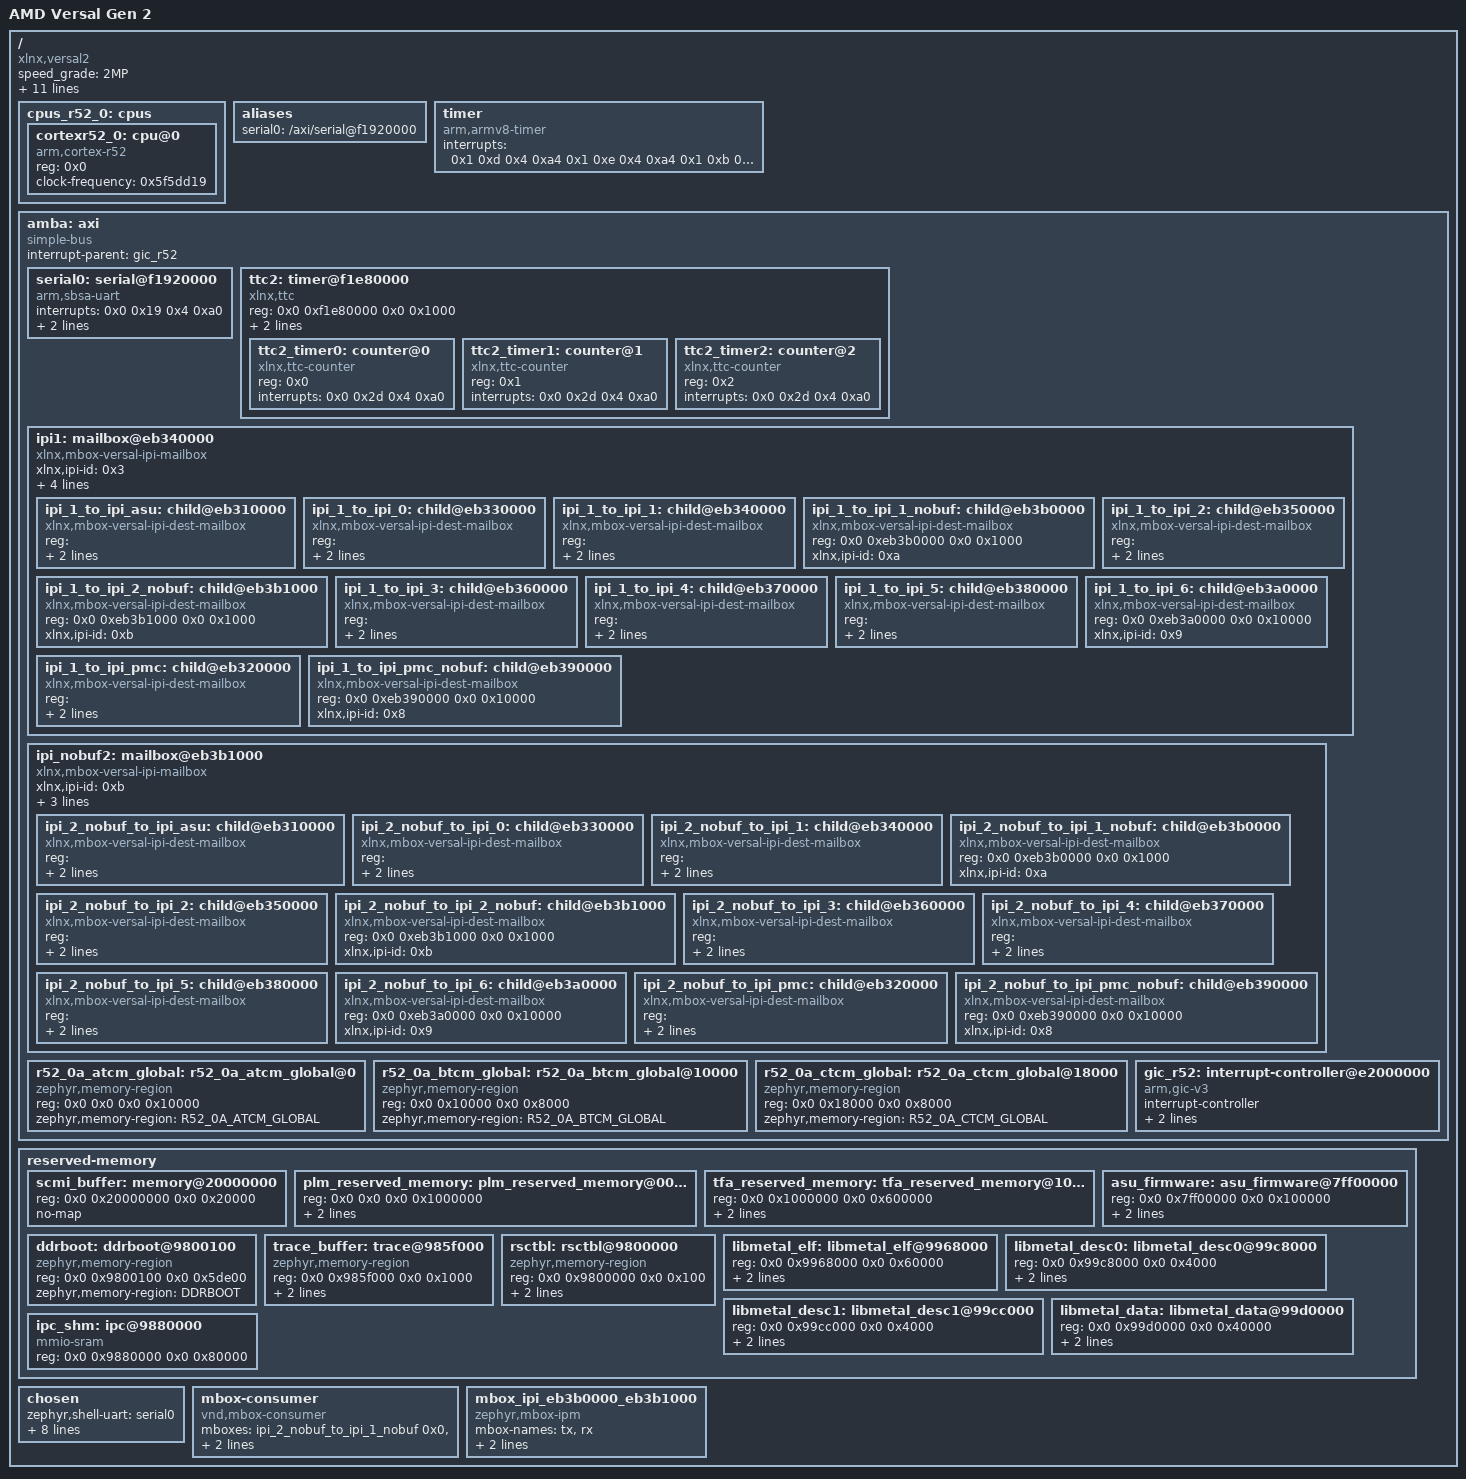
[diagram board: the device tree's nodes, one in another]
/dts-v1/;
/ {
        speed_grade = "2MP";
        family = "Versal_2VE_2VM";
        slrcount = <0x1>;
        variant = "Versal_2VE_2VM_Small";
        xlnx,ddrmc5-i2c-master = "PMC";
        xlnx,ddrmc5-debug-elf = "false";
        device_id = "xc2vm3654";
        vivado-version = "2026.2";
        board = "vmk365";
        interrupt-parent = <&gic_r52>;
        #size-cells = <0x2>;
        #address-cells = <0x2>;
        model = "AMD Versal Gen 2";
        compatible = "xlnx,versal2";
        pruned-sdt = <0x1>;

        cpus_r52_0: cpus {
                phandle = <0xfb>;
                #size-cells = <0x0>;
                #address-cells = <0x1>;

                cortexr52_0: cpu@0 {
                        phandle = <0xb8>;
                        reg = <0x0>;
                        device_type = "cpu";
                        compatible = "arm,cortex-r52";
                        clock-frequency = <0x5f5dd19>;
                };
        };

        aliases {
                serial0 = "/axi/serial@f1920000";
        };

        timer: timer {
                phandle = <0x116>;
                interrupts = <0x1 0xd 0x4 0xa4 0x1 0xe 0x4 0xa4 0x1 0xb 0x4 0xa4 0x1 0xa 0x4 0xa4>;
                compatible = "arm,armv8-timer";
        };

        amba: axi {
                phandle = <0x2>;
                interrupt-parent = <&gic_r52>;
                ranges;
                #size-cells = <0x2>;
                #address-cells = <0x2>;
                bootph-all;
                compatible = "simple-bus";

                serial0: serial@f1920000 {
                        phandle = <0x93>;
                        interrupts = <0x0 0x19 0x4 0xa0>;
                        interrupt-parent = <&gic_r52>;
                        reg = <0x0 0xf1920000 0x0 0x1000>;
                        status = "okay";
                        compatible = "arm,sbsa-uart";
                        interrupt-names = "serial0";
                };

                ttc2: timer@f1e80000 {
                        phandle = <0x9e>;
                        reg = <0x0 0xf1e80000 0x0 0x1000>;
                        timer-width = <0x20>;
                        status = "okay";
                        compatible = "xlnx,ttc";
                        clock-frequency = <0x8f0cba9>;
                        #address-cells = <0x1>;
                        #size-cells = <0x0>;

                        ttc2_timer0: counter@0 {
                                phandle = <0x1>;
                                compatible = "xlnx,ttc-counter";
                                reg = <0x0>;
                                interrupts = <0x0 0x2d 0x4 0xa0>;
                        };

                        ttc2_timer1: counter@1 {
                                phandle = <0x3>;
                                compatible = "xlnx,ttc-counter";
                                reg = <0x1>;
                                interrupts = <0x0 0x2d 0x4 0xa0>;
                        };

                        ttc2_timer2: counter@2 {
                                phandle = <0x4>;
                                compatible = "xlnx,ttc-counter";
                                reg = <0x2>;
                                interrupts = <0x0 0x2d 0x4 0xa0>;
                        };
                };

                ipi1: mailbox@eb340000 {
                        phandle = <0xb4>;
                        reg-names = "ctrl", "msg";
                        #size-cells = <0x2>;
                        #address-cells = <0x2>;
                        xlnx,ipi-id = <0x3>;
                        reg = <0x0 0xeb340000 0x0 0x10000 0x0 0xeb3f0600 0x0 0x200>;
                        interrupts = <0x0 0x3a 0x4 0xa0>;
                        interrupt-parent = <&gic_r52>;
                        compatible = "xlnx,mbox-versal-ipi-mailbox";

                        ipi_1_to_ipi_asu: child@eb310000 {
                                phandle = <0x15e>;
                                reg-names = "ctrl", "msg";
                                reg = <0x0 0xeb310000 0x0 0x10000 0x0 0xeb3f0000 0x0 0x200>;
                                xlnx,ipi-id = <0x0>;
                                #mbox-cells = <0x1>;
                                compatible = "xlnx,mbox-versal-ipi-dest-mailbox";
                        };

                        ipi_1_to_ipi_0: child@eb330000 {
                                phandle = <0x15f>;
                                reg-names = "ctrl", "msg";
                                reg = <0x0 0xeb330000 0x0 0x10000 0x0 0xeb3f0400 0x0 0x200>;
                                xlnx,ipi-id = <0x2>;
                                #mbox-cells = <0x1>;
                                compatible = "xlnx,mbox-versal-ipi-dest-mailbox";
                        };

                        ipi_1_to_ipi_1: child@eb340000 {
                                phandle = <0x160>;
                                reg-names = "ctrl", "msg";
                                reg = <0x0 0xeb340000 0x0 0x10000 0x0 0xeb3f0600 0x0 0x200>;
                                xlnx,ipi-id = <0x3>;
                                #mbox-cells = <0x1>;
                                compatible = "xlnx,mbox-versal-ipi-dest-mailbox";
                        };

                        ipi_1_to_ipi_1_nobuf: child@eb3b0000 {
                                phandle = <0x161>;
                                reg-names = "ctrl";
                                reg = <0x0 0xeb3b0000 0x0 0x1000>;
                                xlnx,ipi-id = <0xa>;
                                #mbox-cells = <0x1>;
                                compatible = "xlnx,mbox-versal-ipi-dest-mailbox";
                        };

                        ipi_1_to_ipi_2: child@eb350000 {
                                phandle = <0x162>;
                                reg-names = "ctrl", "msg";
                                reg = <0x0 0xeb350000 0x0 0x10000 0x0 0xeb3f0800 0x0 0x200>;
                                xlnx,ipi-id = <0x4>;
                                #mbox-cells = <0x1>;
                                compatible = "xlnx,mbox-versal-ipi-dest-mailbox";
                        };

                        ipi_1_to_ipi_2_nobuf: child@eb3b1000 {
                                phandle = <0x163>;
                                reg-names = "ctrl";
                                reg = <0x0 0xeb3b1000 0x0 0x1000>;
                                xlnx,ipi-id = <0xb>;
                                #mbox-cells = <0x1>;
                                compatible = "xlnx,mbox-versal-ipi-dest-mailbox";
                        };

                        ipi_1_to_ipi_3: child@eb360000 {
                                phandle = <0x164>;
                                reg-names = "ctrl", "msg";
                                reg = <0x0 0xeb360000 0x0 0x10000 0x0 0xeb3f0a00 0x0 0x200>;
                                xlnx,ipi-id = <0x5>;
                                #mbox-cells = <0x1>;
                                compatible = "xlnx,mbox-versal-ipi-dest-mailbox";
                        };

                        ipi_1_to_ipi_4: child@eb370000 {
                                phandle = <0x165>;
                                reg-names = "ctrl", "msg";
                                reg = <0x0 0xeb370000 0x0 0x10000 0x0 0xeb3f0c00 0x0 0x200>;
                                xlnx,ipi-id = <0x6>;
                                #mbox-cells = <0x1>;
                                compatible = "xlnx,mbox-versal-ipi-dest-mailbox";
                        };

                        ipi_1_to_ipi_5: child@eb380000 {
                                phandle = <0x166>;
                                reg-names = "ctrl", "msg";
                                reg = <0x0 0xeb380000 0x0 0x10000 0x0 0xeb3f0e00 0x0 0x200>;
                                xlnx,ipi-id = <0x7>;
                                #mbox-cells = <0x1>;
                                compatible = "xlnx,mbox-versal-ipi-dest-mailbox";
                        };

                        ipi_1_to_ipi_6: child@eb3a0000 {
                                phandle = <0x167>;
                                reg-names = "ctrl";
                                reg = <0x0 0xeb3a0000 0x0 0x10000>;
                                xlnx,ipi-id = <0x9>;
                                #mbox-cells = <0x1>;
                                compatible = "xlnx,mbox-versal-ipi-dest-mailbox";
                        };

                        ipi_1_to_ipi_pmc: child@eb320000 {
                                phandle = <0x168>;
                                reg-names = "ctrl", "msg";
                                reg = <0x0 0xeb320000 0x0 0x10000 0x0 0xeb3f0200 0x0 0x200>;
                                xlnx,ipi-id = <0x1>;
                                #mbox-cells = <0x1>;
                                compatible = "xlnx,mbox-versal-ipi-dest-mailbox";
                        };

                        ipi_1_to_ipi_pmc_nobuf: child@eb390000 {
                                phandle = <0x169>;
                                reg-names = "ctrl";
                                reg = <0x0 0xeb390000 0x0 0x10000>;
                                xlnx,ipi-id = <0x8>;
                                #mbox-cells = <0x1>;
                                compatible = "xlnx,mbox-versal-ipi-dest-mailbox";
                        };
                };

                ipi_nobuf2: mailbox@eb3b1000 {
                        phandle = <0xb5>;
                        reg-names = "ctrl";
                        #size-cells = <0x2>;
                        #address-cells = <0x2>;
                        xlnx,ipi-id = <0xb>;
                        reg = <0x0 0xeb3b1000 0x0 0x1000>;
                        interrupts = <0x0 0x41 0x4 0xa0>;
                        interrupt-parent = <&gic_r52>;
                        compatible = "xlnx,mbox-versal-ipi-mailbox";

                        ipi_2_nobuf_to_ipi_asu: child@eb310000 {
                                phandle = <0x1b2>;
                                reg-names = "ctrl", "msg";
                                reg = <0x0 0xeb310000 0x0 0x10000 0x0 0xeb3f0000 0x0 0x200>;
                                xlnx,ipi-id = <0x0>;
                                #mbox-cells = <0x1>;
                                compatible = "xlnx,mbox-versal-ipi-dest-mailbox";
                        };

                        ipi_2_nobuf_to_ipi_0: child@eb330000 {
                                phandle = <0x1b3>;
                                reg-names = "ctrl", "msg";
                                reg = <0x0 0xeb330000 0x0 0x10000 0x0 0xeb3f0400 0x0 0x200>;
                                xlnx,ipi-id = <0x2>;
                                #mbox-cells = <0x1>;
                                compatible = "xlnx,mbox-versal-ipi-dest-mailbox";
                        };

                        ipi_2_nobuf_to_ipi_1: child@eb340000 {
                                phandle = <0x1b4>;
                                reg-names = "ctrl", "msg";
                                reg = <0x0 0xeb340000 0x0 0x10000 0x0 0xeb3f0600 0x0 0x200>;
                                xlnx,ipi-id = <0x3>;
                                #mbox-cells = <0x1>;
                                compatible = "xlnx,mbox-versal-ipi-dest-mailbox";
                        };

                        ipi_2_nobuf_to_ipi_1_nobuf: child@eb3b0000 {
                                phandle = <0x1b5>;
                                reg-names = "ctrl";
                                reg = <0x0 0xeb3b0000 0x0 0x1000>;
                                xlnx,ipi-id = <0xa>;
                                #mbox-cells = <0x1>;
                                compatible = "xlnx,mbox-versal-ipi-dest-mailbox";
                        };

                        ipi_2_nobuf_to_ipi_2: child@eb350000 {
                                phandle = <0x1b6>;
                                reg-names = "ctrl", "msg";
                                reg = <0x0 0xeb350000 0x0 0x10000 0x0 0xeb3f0800 0x0 0x200>;
                                xlnx,ipi-id = <0x4>;
                                #mbox-cells = <0x1>;
                                compatible = "xlnx,mbox-versal-ipi-dest-mailbox";
                        };

                        ipi_2_nobuf_to_ipi_2_nobuf: child@eb3b1000 {
                                phandle = <0x1b7>;
                                reg-names = "ctrl";
                                reg = <0x0 0xeb3b1000 0x0 0x1000>;
                                xlnx,ipi-id = <0xb>;
                                #mbox-cells = <0x1>;
                                compatible = "xlnx,mbox-versal-ipi-dest-mailbox";
                        };

                        ipi_2_nobuf_to_ipi_3: child@eb360000 {
                                phandle = <0x1b8>;
                                reg-names = "ctrl", "msg";
                                reg = <0x0 0xeb360000 0x0 0x10000 0x0 0xeb3f0a00 0x0 0x200>;
                                xlnx,ipi-id = <0x5>;
                                #mbox-cells = <0x1>;
                                compatible = "xlnx,mbox-versal-ipi-dest-mailbox";
                        };

                        ipi_2_nobuf_to_ipi_4: child@eb370000 {
                                phandle = <0x1b9>;
                                reg-names = "ctrl", "msg";
                                reg = <0x0 0xeb370000 0x0 0x10000 0x0 0xeb3f0c00 0x0 0x200>;
                                xlnx,ipi-id = <0x6>;
                                #mbox-cells = <0x1>;
                                compatible = "xlnx,mbox-versal-ipi-dest-mailbox";
                        };

                        ipi_2_nobuf_to_ipi_5: child@eb380000 {
                                phandle = <0x1ba>;
                                reg-names = "ctrl", "msg";
                                reg = <0x0 0xeb380000 0x0 0x10000 0x0 0xeb3f0e00 0x0 0x200>;
                                xlnx,ipi-id = <0x7>;
                                #mbox-cells = <0x1>;
                                compatible = "xlnx,mbox-versal-ipi-dest-mailbox";
                        };

                        ipi_2_nobuf_to_ipi_6: child@eb3a0000 {
                                phandle = <0x1bb>;
                                reg-names = "ctrl";
                                reg = <0x0 0xeb3a0000 0x0 0x10000>;
                                xlnx,ipi-id = <0x9>;
                                #mbox-cells = <0x1>;
                                compatible = "xlnx,mbox-versal-ipi-dest-mailbox";
                        };

                        ipi_2_nobuf_to_ipi_pmc: child@eb320000 {
                                phandle = <0x1bc>;
                                reg-names = "ctrl", "msg";
                                reg = <0x0 0xeb320000 0x0 0x10000 0x0 0xeb3f0200 0x0 0x200>;
                                xlnx,ipi-id = <0x1>;
                                #mbox-cells = <0x1>;
                                compatible = "xlnx,mbox-versal-ipi-dest-mailbox";
                        };

                        ipi_2_nobuf_to_ipi_pmc_nobuf: child@eb390000 {
                                phandle = <0x1bd>;
                                reg-names = "ctrl";
                                reg = <0x0 0xeb390000 0x0 0x10000>;
                                xlnx,ipi-id = <0x8>;
                                #mbox-cells = <0x1>;
                                compatible = "xlnx,mbox-versal-ipi-dest-mailbox";
                        };
                };

                r52_0a_atcm_global: r52_0a_atcm_global@0 {
                        phandle = <0x21>;
                        reg = <0x0 0x0 0x0 0x10000>;
                        compatible = "zephyr,memory-region", "xlnx,tcm";
                        status = "okay";
                        zephyr,memory-region = "R52_0A_ATCM_GLOBAL";
                };

                r52_0a_btcm_global: r52_0a_btcm_global@10000 {
                        phandle = <0x22>;
                        reg = <0x0 0x10000 0x0 0x8000>;
                        compatible = "zephyr,memory-region", "xlnx,tcm";
                        status = "okay";
                        zephyr,memory-region = "R52_0A_BTCM_GLOBAL";
                };

                r52_0a_ctcm_global: r52_0a_ctcm_global@18000 {
                        phandle = <0x23>;
                        reg = <0x0 0x18000 0x0 0x8000>;
                        compatible = "zephyr,memory-region", "xlnx,tcm";
                        status = "okay";
                        zephyr,memory-region = "R52_0A_CTCM_GLOBAL";
                };

                gic_r52: interrupt-controller@e2000000 {
                        phandle = <0xb6>;
                        compatible = "arm,gic-v3", "arm,gic";
                        #interrupt-cells = <0x4>;
                        interrupt-controller;
                        reg = <0x0 0xe2000000 0x0 0x10000 0x0 0xe2100000 0x0 0x80000>;
                        status = "okay";
                };
        };

        reserved-memory {
                #address-cells = <0x2>;
                #size-cells = <0x2>;
                ranges;

                scmi_buffer: memory@20000000 {
                        phandle = <0x1ed>;
                        reg = <0x0 0x20000000 0x0 0x20000>;
                        no-map;
                };

                plm_reserved_memory: plm_reserved_memory@00000000 {
                        phandle = <0x1fd>;
                        reg = <0x0 0x0 0x0 0x1000000>;
                        no-map;
                        label = "plm_reserved_memory";
                };

                tfa_reserved_memory: tfa_reserved_memory@1000000 {
                        phandle = <0x1fe>;
                        reg = <0x0 0x1000000 0x0 0x600000>;
                        no-map;
                        label = "tfa_reserved_memory";
                };

                asu_firmware: asu_firmware@7ff00000 {
                        phandle = <0x201>;
                        reg = <0x0 0x7ff00000 0x0 0x100000>;
                        no-map;
                        label = "asu_firmware";
                };

                ddrboot: ddrboot@9800100 {
                        phandle = <0x205>;
                        reg = <0x0 0x9800100 0x0 0x5de00>;
                        compatible = "zephyr,memory-region";
                        zephyr,memory-region = "DDRBOOT";
                };

                trace_buffer: trace@985f000 {
                        phandle = <0x206>;
                        reg = <0x0 0x985f000 0x0 0x1000>;
                        compatible = "zephyr,memory-region";
                        zephyr,memory-region = "TRACE_BUFFER";
                        zephyr,memory-attr = <0x200000>;
                };

                rsctbl: rsctbl@9800000 {
                        phandle = <0x207>;
                        reg = <0x0 0x9800000 0x0 0x100>;
                        compatible = "zephyr,memory-region";
                        zephyr,memory-region = "RSCTBL";
                        zephyr,memory-attr = <0x200000>;
                };

                libmetal_elf: libmetal_elf@9968000 {
                        phandle = <0x20e>;
                        reg = <0x0 0x9968000 0x0 0x60000>;
                        no-map;
                        label = "libmetal_elf";
                };

                libmetal_desc0: libmetal_desc0@99c8000 {
                        phandle = <0x20b>;
                        reg = <0x0 0x99c8000 0x0 0x4000>;
                        no-map;
                        label = "libmetal_desc0";
                };

                libmetal_desc1: libmetal_desc1@99cc000 {
                        phandle = <0x20c>;
                        reg = <0x0 0x99cc000 0x0 0x4000>;
                        no-map;
                        label = "libmetal_desc1";
                };

                libmetal_data: libmetal_data@99d0000 {
                        phandle = <0x20d>;
                        reg = <0x0 0x99d0000 0x0 0x40000>;
                        no-map;
                        label = "libmetal_data";
                };

                ipc_shm: ipc@9880000 {
                        phandle = <0x20f>;
                        reg = <0x0 0x9880000 0x0 0x80000>;
                        compatible = "mmio-sram";
                        status = "okay";
                };
        };

        chosen {
                zephyr,shell-uart = "serial0";
                zephyr,console = "serial0";
                bootargs = "console=ttyAMA0,115200";
                stdout-path = "serial0:115200n8";
                zephyr,ram-console = "/reserved-memory/trace@985f000";
                zephyr,ipc_shm = "/reserved-memory/ipc@9880000";
                zephyr,sram = "/axi/r52_0a_atcm_global@0";
                zephyr,ipc = "/mbox_ipi_eb3b0000_eb3b1000";
        };

        mbox-consumer {
                compatible = "vnd,mbox-consumer";
                mboxes = <&ipi_2_nobuf_to_ipi_1_nobuf 0x0>,
                 <&ipi_2_nobuf_to_ipi_1_nobuf 0x1>;
                mbox-names = "tx", "rx";
        };

        mbox_ipi_eb3b0000_eb3b1000 {
                compatible = "zephyr,mbox-ipm";
                mbox-names = "tx", "rx";
                status = "okay";
                mboxes = <&ipi_2_nobuf_to_ipi_1_nobuf 0x0>,
                 <&ipi_2_nobuf_to_ipi_1_nobuf 0x1>;
        };

        __symbols__ {
                cpus_r52_0 = "/cpus";
                cortexr52_0 = "/cpus/cpu@0";
                timer = "/timer";
                amba = "/axi";
                serial0 = "/axi/serial@f1920000";
                ttc2 = "/axi/timer@f1e80000";
                ttc2_timer0 = "/axi/timer@f1e80000/counter@0";
                ttc2_timer1 = "/axi/timer@f1e80000/counter@1";
                ttc2_timer2 = "/axi/timer@f1e80000/counter@2";
                ipi1 = "/axi/mailbox@eb340000";
                ipi_1_to_ipi_asu = "/axi/mailbox@eb340000/child@eb310000";
                ipi_1_to_ipi_0 = "/axi/mailbox@eb340000/child@eb330000";
                ipi_1_to_ipi_1 = "/axi/mailbox@eb340000/child@eb340000";
                ipi_1_to_ipi_1_nobuf = "/axi/mailbox@eb340000/child@eb3b0000";
                ipi_1_to_ipi_2 = "/axi/mailbox@eb340000/child@eb350000";
                ipi_1_to_ipi_2_nobuf = "/axi/mailbox@eb340000/child@eb3b1000";
                ipi_1_to_ipi_3 = "/axi/mailbox@eb340000/child@eb360000";
                ipi_1_to_ipi_4 = "/axi/mailbox@eb340000/child@eb370000";
                ipi_1_to_ipi_5 = "/axi/mailbox@eb340000/child@eb380000";
                ipi_1_to_ipi_6 = "/axi/mailbox@eb340000/child@eb3a0000";
                ipi_1_to_ipi_pmc = "/axi/mailbox@eb340000/child@eb320000";
                ipi_1_to_ipi_pmc_nobuf = "/axi/mailbox@eb340000/child@eb390000";
                ipi_nobuf2 = "/axi/mailbox@eb3b1000";
                ipi_2_nobuf_to_ipi_asu = "/axi/mailbox@eb3b1000/child@eb310000";
                ipi_2_nobuf_to_ipi_0 = "/axi/mailbox@eb3b1000/child@eb330000";
                ipi_2_nobuf_to_ipi_1 = "/axi/mailbox@eb3b1000/child@eb340000";
                ipi_2_nobuf_to_ipi_1_nobuf = "/axi/mailbox@eb3b1000/child@eb3b0000";
                ipi_2_nobuf_to_ipi_2 = "/axi/mailbox@eb3b1000/child@eb350000";
                ipi_2_nobuf_to_ipi_2_nobuf = "/axi/mailbox@eb3b1000/child@eb3b1000";
                ipi_2_nobuf_to_ipi_3 = "/axi/mailbox@eb3b1000/child@eb360000";
                ipi_2_nobuf_to_ipi_4 = "/axi/mailbox@eb3b1000/child@eb370000";
                ipi_2_nobuf_to_ipi_5 = "/axi/mailbox@eb3b1000/child@eb380000";
                ipi_2_nobuf_to_ipi_6 = "/axi/mailbox@eb3b1000/child@eb3a0000";
                ipi_2_nobuf_to_ipi_pmc = "/axi/mailbox@eb3b1000/child@eb320000";
                ipi_2_nobuf_to_ipi_pmc_nobuf = "/axi/mailbox@eb3b1000/child@eb390000";
                r52_0a_atcm_global = "/axi/r52_0a_atcm_global@0";
                r52_0a_btcm_global = "/axi/r52_0a_btcm_global@10000";
                r52_0a_ctcm_global = "/axi/r52_0a_ctcm_global@18000";
                gic_r52 = "/axi/interrupt-controller@e2000000";
                scmi_buffer = "/reserved-memory/memory@20000000";
                plm_reserved_memory = "/reserved-memory/plm_reserved_memory@00000000";
                tfa_reserved_memory = "/reserved-memory/tfa_reserved_memory@1000000";
                asu_firmware = "/reserved-memory/asu_firmware@7ff00000";
                ddrboot = "/reserved-memory/ddrboot@9800100";
                trace_buffer = "/reserved-memory/trace@985f000";
                rsctbl = "/reserved-memory/rsctbl@9800000";
                libmetal_elf = "/reserved-memory/libmetal_elf@9968000";
                libmetal_desc0 = "/reserved-memory/libmetal_desc0@99c8000";
                libmetal_desc1 = "/reserved-memory/libmetal_desc1@99cc000";
                libmetal_data = "/reserved-memory/libmetal_data@99d0000";
                ipc_shm = "/reserved-memory/ipc@9880000";
        };
};
